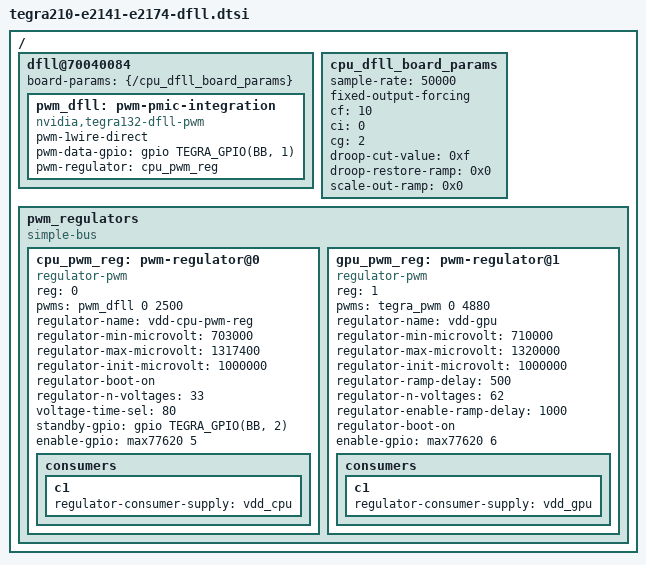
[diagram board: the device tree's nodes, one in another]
#include <dt-bindings/gpio/tegra-gpio.h>

/ {
	dfll@70040084 {
		board-params = <&{/cpu_dfll_board_params}>;
		status = "okay";
		pwm_dfll: pwm-pmic-integration {
			compatible = "nvidia,tegra132-dfll-pwm";
			pwm-1wire-direct;
			pwm-data-gpio = <&gpio TEGRA_GPIO(BB, 1) 0>;
			#pwm-cells = <2>;
			pwm-regulator = <&cpu_pwm_reg>;
		};
	};

	cpu_dfll_board_params {
		sample-rate = <50000>;
		fixed-output-forcing;
		cf = <10>;
		ci = <0>;
		cg = <2>;
		droop-cut-value = <0xf>;
		droop-restore-ramp = <0x0>;
		scale-out-ramp = <0x0>;
	};

	pwm_regulators {
		compatible = "simple-bus";
		#address-cells = <1>;
		#size-cells = <0>;

		cpu_pwm_reg: pwm-regulator@0 {
			reg = <0>;
			compatible = "regulator-pwm";
			pwms = <&pwm_dfll 0 2500>;
			regulator-name = "vdd-cpu-pwm-reg";
			regulator-min-microvolt = <703000>;
			regulator-max-microvolt = <1317400>;
			regulator-init-microvolt = <1000000>;
			regulator-boot-on;
			regulator-n-voltages = <33>;
			voltage-time-sel = <80>;
			standby-gpio = <&gpio TEGRA_GPIO(BB, 2) 0>;
			enable-gpio = <&max77620 5 0>;
			consumers {
				c1 {
					regulator-consumer-supply = "vdd_cpu";
				};
			};
		};
		gpu_pwm_reg: pwm-regulator@1 {
			reg = <1>;
			compatible = "regulator-pwm";
			pwms = <&tegra_pwm 0 4880>;
			regulator-name = "vdd-gpu";
			regulator-min-microvolt = <710000>;
			regulator-max-microvolt = <1320000>;
			regulator-init-microvolt = <1000000>;
			regulator-ramp-delay = <500>;
			regulator-n-voltages = <62>;
			regulator-enable-ramp-delay = <1000>;
			regulator-boot-on;
			enable-gpio = <&max77620 6 0>;
			consumers {
				c1 {
					regulator-consumer-supply = "vdd_gpu";
				};
			};
		};
	};
};
